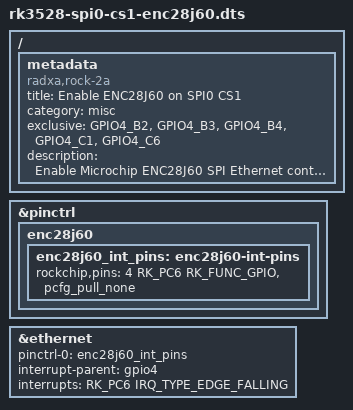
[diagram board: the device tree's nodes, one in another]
#define ENC28J60_SPI spi0
#define SPIDEV_NUM 1
#include "enc28j60.dtsi"

/ {
	metadata {
		title = "Enable ENC28J60 on SPI0 CS1";
		compatible = "radxa,rock-2a", "radxa,rock-2f", "radxa,medge-rk3528a-io";
		category = "misc";
		exclusive = "GPIO4_B2", "GPIO4_B3", "GPIO4_B4", "GPIO4_C1", "GPIO4_C6";
		description = "Enable Microchip ENC28J60 SPI Ethernet controller on SPI0 CS1.
INT=15";
	};
};

&pinctrl {
	enc28j60 {
		enc28j60_int_pins: enc28j60-int-pins {
			rockchip,pins = <4 RK_PC6 RK_FUNC_GPIO &pcfg_pull_none>;
		};
	};
};

&ethernet {
	pinctrl-names = "default";
	pinctrl-0 = <&enc28j60_int_pins>;
	interrupt-parent = <&gpio4>;
	interrupts = <RK_PC6 IRQ_TYPE_EDGE_FALLING>;
};
